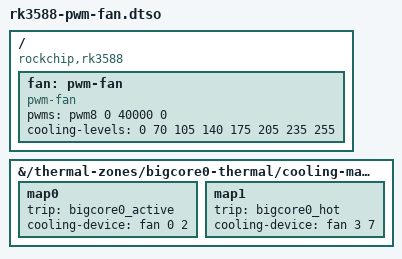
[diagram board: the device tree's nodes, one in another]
/dts-v1/;
/plugin/;

/ {
        compatible = "rockchip,rk3588";   /* lets the loader know this overlay fits */

        /* ------------------------------------------------------------------ */
        /* 2.1  Create or patch the pwm-fan node                              */
        /* ------------------------------------------------------------------ */
        fragment@0 {
                /* the base DT for Rock-5 C has no pwm-fan node,
                 * so we target the root ("/") and add one.
                 */
                target-path = "/";
                __overlay__ {
                        fan: pwm-fan {
                                compatible      = "pwm-fan";

                                /* -- PWM8 channel 0, 25 kHz, active-high -- */
                                pwms            = <&pwm8 0 40000 0>;

                                /* Nine duty steps from “barely spinning” to full */
                                cooling-levels  = <0 70 105 140 175 205 235 255>;
                                #cooling-cells  = <2>; /* <min max> */
                        };
                };
        };

        /* ------------------------------------------------------------------ */
        /* 2.2  Hook that fan into the big-core thermal zone                   */
        /* ------------------------------------------------------------------ */
        fragment@1 {
                /* pick the existing thermal zone for the A76 cluster */
                target-path = "/thermal-zones/bigcore0-thermal/cooling-maps";

                __overlay__ {
                        map0 {
                                /* trip@55 °C → fan levels 0-2   */
                                /* the trips already exist in the base dtb        */
                                trip            = <&bigcore0_active>;
                                cooling-device  = <&fan 0 2>;
                        };

                        map1 {
                                /* trip@70 °C → fan levels 3-7   */
                                trip            = <&bigcore0_hot>;
                                cooling-device  = <&fan 3 7>;
                        };
                };
        };
};
